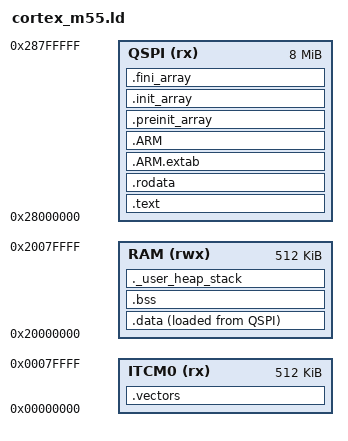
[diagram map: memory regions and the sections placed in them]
ENTRY(Reset_Handler)

/* Highest address of the user mode stack */
_estack = ORIGIN(RAM) + LENGTH(RAM);    /* end of RAM */
/* Generate a link error if heap and stack don't fit into RAM */
_Min_Heap_Size = 0x10000;      /* required amount of heap  */
_Min_Stack_Size = 0x10000; /* required amount of stack */
/* Memory layout for Cortex-M55 */
MEMORY
{
    ITCM0 (rx)    : ORIGIN = 0x00000000, LENGTH = 512K
    QSPI  (rx)    : ORIGIN = 0x28000000, LENGTH = 8M
    RAM   (rwx)   : ORIGIN = 0x20000000, LENGTH = 512K
}

SECTIONS
{
    .vectors :
    {
        . = ALIGN(4);
        KEEP(*(.vectors))
        . = ALIGN(4);
    } > ITCM0

    .text :
    {
        . = ALIGN(4);
        *(.text)           /* .text sections (code) */
        *(.text*)          /* .text* sections (code) */
        *(.glue_7)         /* glue arm to thumb code */
        *(.glue_7t)        /* glue thumb to arm code */
        *(.eh_frame)

        KEEP (*(.init))
        KEEP (*(.fini))
        . = ALIGN(4);
        _etext = .;
    } > QSPI

    .rodata :
    {
        . = ALIGN(4);
        *(.rodata)
        *(.rodata*)
        . = ALIGN(4);
    } > QSPI

    .ARM.extab (READONLY) : /* The "READONLY" keyword is only supported in GCC11 and later, remove it if using GCC10 or earlier. */
    {
        . = ALIGN(4);
        *(.ARM.extab* .gnu.linkonce.armextab.*)
        . = ALIGN(4);
    } > QSPI

    .ARM (READONLY) : /* The "READONLY" keyword is only supported in GCC11 and later, remove it if using GCC10 or earlier. */
    {
        . = ALIGN(4);
        __exidx_start = .;
        *(.ARM.exidx*)
        __exidx_end = .;
        . = ALIGN(4);
    } > QSPI

    .preinit_array (READONLY):
    {
        . = ALIGN(4);
        PROVIDE_HIDDEN (__preinit_array_start = .);
        KEEP(*(.preinit_array))
        PROVIDE_HIDDEN (__preinit_array_end = .);
        . = ALIGN(4);
    } > QSPI

    .init_array (READONLY):
    {
        . = ALIGN(4);
        PROVIDE_HIDDEN (__init_array_start = .);
        KEEP(*(SORT(.init_array.*)))
        KEEP(*(.init_array))
        PROVIDE_HIDDEN (__init_array_end = .);
        . = ALIGN(4);
    } > QSPI

    .fini_array (READONLY):
    {
        . = ALIGN(4);
        PROVIDE_HIDDEN (__fini_array_start = .);
        KEEP(*(SORT(.fini_array.*)))
        KEEP(*(.fini_array))
        PROVIDE_HIDDEN (__fini_array_end = .);
        . = ALIGN(4);
    } > QSPI

    /* Initialized data in RAM (copied from ITCM0) */
    __data_init__ = LOADADDR(.data);
    .data :
    {
        . = ALIGN(4);
        __data_start__ = .;
        *(.data)
        *(.data*)
        . = ALIGN(4);
        __data_end__ = .;
    } > RAM AT > QSPI

    /* Uninitialized data in RAM */
    . = ALIGN(4);
    .bss (NOLOAD) :
    {
        __bss_start__ = .;
        *(.bss)
        *(.bss*)
        *(COMMON)
        . = ALIGN(4);
        __bss_end__ = .;
    } > RAM

    /* User_heap_stack section, used to check that there is enough RAM left */
    ._user_heap_stack :
    {
        . = ALIGN(8);
        PROVIDE ( end = . );
        PROVIDE ( _end = . );
        . = . + _Min_Heap_Size;
        . = . + _Min_Stack_Size;
        . = ALIGN(8);
    } >RAM
}
